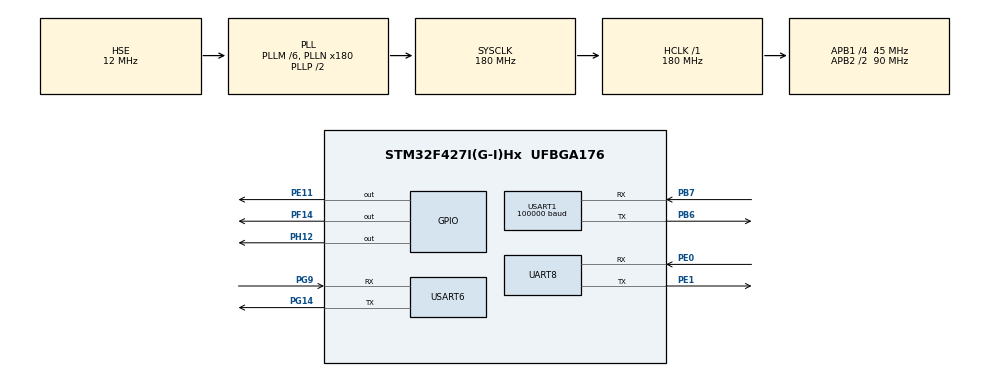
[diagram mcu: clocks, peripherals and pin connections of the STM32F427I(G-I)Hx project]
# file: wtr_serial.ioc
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Dma.Request0=USART1_RX
Dma.USART1_RX.0.Direction=DMA_PERIPH_TO_MEMORY
Dma.USART1_RX.0.FIFOMode=DMA_FIFOMODE_DISABLE
Dma.USART1_RX.0.Instance=DMA2_Stream2
Dma.USART1_RX.0.MemDataAlignment=DMA_MDATAALIGN_BYTE
Dma.USART1_RX.0.MemInc=DMA_MINC_ENABLE
Dma.USART1_RX.0.Mode=DMA_CIRCULAR
Dma.USART1_RX.0.PeriphDataAlignment=DMA_PDATAALIGN_BYTE
Dma.USART1_RX.0.PeriphInc=DMA_PINC_DISABLE
Dma.USART1_RX.0.Priority=DMA_PRIORITY_LOW
FREERTOS.Tasks01=defaultTask,0,256,StartDefaultTask,As weak,NULL,Dynamic,NULL,NULL
FREERTOS.configENABLE_FPU=1
FREERTOS.configGENERATE_RUN_TIME_STATS=1
FREERTOS.configTOTAL_HEAP_SIZE=65536
FREERTOS.configUSE_COUNTING_SEMAPHORES=1
FREERTOS.configUSE_NEWLIB_REENTRANT=1
FREERTOS.configUSE_RECURSIVE_MUTEXES=1
FREERTOS.configUSE_STATS_FORMATTING_FUNCTIONS=1
FREERTOS.configUSE_TRACE_FACILITY=1
Mcu.Family=STM32F4
Mcu.Name=STM32F427I(G-I)Hx
Mcu.Package=UFBGA176
NVIC.DMA2_Stream2_IRQn=true\:5\:0\:false\:false\:true\:true\:false\:true\:true
NVIC.PriorityGroup=NVIC_PRIORITYGROUP_4
NVIC.TIM7_IRQn=true\:15\:0\:false\:false\:true\:false\:false\:true\:true
NVIC.TimeBase=TIM7_IRQn
NVIC.TimeBaseIP=TIM7
NVIC.UART8_IRQn=true\:5\:0\:false\:false\:true\:true\:true\:true\:true
NVIC.USART6_IRQn=true\:5\:0\:false\:false\:true\:true\:true\:true\:true
PA13.Mode=Serial_Wire
PA13.Signal=SYS_JTMS-SWDIO
PA14.Mode=Serial_Wire
PA14.Signal=SYS_JTCK-SWCLK
PB6.Mode=Asynchronous
PB6.Signal=USART1_TX
PB7.Mode=Asynchronous
PB7.Signal=USART1_RX
PE0.Mode=Asynchronous
PE0.Signal=UART8_RX
PE1.Mode=Asynchronous
PE1.Signal=UART8_TX
PE11.Signal=GPIO_Output
PF14.Signal=GPIO_Output
PG14.Mode=Asynchronous
PG14.Signal=USART6_TX
PG9.Mode=Asynchronous
PG9.Signal=USART6_RX
PH0/OSC_IN.Mode=HSE-External-Oscillator
PH0/OSC_IN.Signal=RCC_OSC_IN
PH1/OSC_OUT.Mode=HSE-External-Oscillator
PH1/OSC_OUT.Signal=RCC_OSC_OUT
PH12.Signal=GPIO_Output
ProjectManager.HeapSize=0x200
ProjectManager.StackSize=0x400
ProjectManager.TargetToolchain=Makefile
RCC.48MHZClocksFreq_Value=90000000
RCC.AHBFreq_Value=180000000
RCC.APB1CLKDivider=RCC_HCLK_DIV4
RCC.APB1Freq_Value=45000000
RCC.APB1TimFreq_Value=90000000
RCC.APB2CLKDivider=RCC_HCLK_DIV2
RCC.APB2Freq_Value=90000000
RCC.APB2TimFreq_Value=180000000
RCC.CortexFreq_Value=180000000
RCC.HCLKFreq_Value=180000000
RCC.HSE_VALUE=12000000
RCC.HSI_VALUE=16000000
RCC.LSE_VALUE=32768
RCC.PLLM=6
RCC.PLLN=180
RCC.PLLSourceVirtual=RCC_PLLSOURCE_HSE
RCC.SYSCLKFreq_VALUE=180000000
RCC.SYSCLKSource=RCC_SYSCLKSOURCE_PLLCLK
RCC.VCOOutputFreq_Value=360000000
UART8.VirtualMode=Asynchronous
USART1.BaudRate=100000
USART1.VirtualMode=VM_ASYNC
USART6.VirtualMode=VM_ASYNC
VP_FREERTOS_VS_CMSIS_V1.Mode=CMSIS_V1
VP_SYS_VS_tim7.Mode=TIM7
board=custom

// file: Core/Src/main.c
/* USER CODE BEGIN Header */
/**
  ******************************************************************************
  * @file           : main.c
  * @brief          : Main program body
  ******************************************************************************
  * @attention
  *
  * Copyright (c) 2023 STMicroelectronics.
  * All rights reserved.
  *
  * This software is licensed under terms that can be found in the LICENSE file
  * in the root directory of this software component.
  * If no LICENSE file comes with this software, it is provided AS-IS.
  *
  ******************************************************************************
  */
/* USER CODE END Header */
#include "main.h"
#include "cmsis_os.h"
#include "dma.h"
#include "usart.h"
#include "gpio.h"

void SystemClock_Config(void);
void MX_FREERTOS_Init(void);

int main(void)
{

  /* MCU Configuration--------------------------------------------------------*/

  /* Reset of all peripherals, Initializes the Flash interface and the Systick. */
  HAL_Init();

  /* Configure the system clock */
  SystemClock_Config();

  /* Initialize all configured peripherals */
  MX_GPIO_Init();
  MX_DMA_Init();
  MX_USART1_UART_Init();
  MX_UART8_Init();
  MX_USART6_UART_Init();

  /* Call init function for freertos objects (in freertos.c) */
  MX_FREERTOS_Init();

  /* Start scheduler */
  osKernelStart();

  /* We should never get here as control is now taken by the scheduler */
  /* Infinite loop */
  /* USER CODE BEGIN WHILE */
  while (1)
  {
    // HAL_GPIO_TogglePin(GPIOE, GPIO_PIN_11);
    // HAL_Delay(1000);
    /* USER CODE END WHILE */

  }
}

void SystemClock_Config(void)
{
  RCC_OscInitTypeDef RCC_OscInitStruct = {0};
  RCC_ClkInitTypeDef RCC_ClkInitStruct = {0};

  /** Configure the main internal regulator output voltage
  */
  __HAL_RCC_PWR_CLK_ENABLE();
  __HAL_PWR_VOLTAGESCALING_CONFIG(PWR_REGULATOR_VOLTAGE_SCALE1);

  /** Initializes the RCC Oscillators according to the specified parameters
  * in the RCC_OscInitTypeDef structure.
  */
  RCC_OscInitStruct.OscillatorType = RCC_OSCILLATORTYPE_HSE;
  RCC_OscInitStruct.HSEState = RCC_HSE_ON;
  RCC_OscInitStruct.PLL.PLLState = RCC_PLL_ON;
  RCC_OscInitStruct.PLL.PLLSource = RCC_PLLSOURCE_HSE;
  RCC_OscInitStruct.PLL.PLLM = 6;
  RCC_OscInitStruct.PLL.PLLN = 180;
  RCC_OscInitStruct.PLL.PLLP = RCC_PLLP_DIV2;
  RCC_OscInitStruct.PLL.PLLQ = 4;
  if (HAL_RCC_OscConfig(&RCC_OscInitStruct) != HAL_OK)
  {
    Error_Handler();
  }

  /** Activate the Over-Drive mode
  */
  if (HAL_PWREx_EnableOverDrive() != HAL_OK)
  {
    Error_Handler();
  }

  /** Initializes the CPU, AHB and APB buses clocks
  */
  RCC_ClkInitStruct.ClockType = RCC_CLOCKTYPE_HCLK|RCC_CLOCKTYPE_SYSCLK
                              |RCC_CLOCKTYPE_PCLK1|RCC_CLOCKTYPE_PCLK2;
  RCC_ClkInitStruct.SYSCLKSource = RCC_SYSCLKSOURCE_PLLCLK;
  RCC_ClkInitStruct.AHBCLKDivider = RCC_SYSCLK_DIV1;
  RCC_ClkInitStruct.APB1CLKDivider = RCC_HCLK_DIV4;
  RCC_ClkInitStruct.APB2CLKDivider = RCC_HCLK_DIV2;

  if (HAL_RCC_ClockConfig(&RCC_ClkInitStruct, FLASH_LATENCY_5) != HAL_OK)
  {
    Error_Handler();
  }
}

void HAL_TIM_PeriodElapsedCallback(TIM_HandleTypeDef *htim)
{
  if (htim->Instance == TIM7) {
    HAL_IncTick();
  }
}

void Error_Handler(void)
{
  __disable_irq();
  while (1)
  {
  }
}

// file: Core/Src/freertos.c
/* USER CODE BEGIN Header */
/**
  ******************************************************************************
  * File Name          : freertos.c
  * Description        : Code for freertos applications
  ******************************************************************************
  * @attention
  *
  * Copyright (c) 2023 STMicroelectronics.
  * All rights reserved.
  *
  * This software is licensed under terms that can be found in the LICENSE file
  * in the root directory of this software component.
  * If no LICENSE file comes with this software, it is provided AS-IS.
  *
  ******************************************************************************
  */
/* USER CODE END Header */

#include "FreeRTOS.h"
#include "task.h"
#include "main.h"
#include "cmsis_os.h"

/* USER CODE BEGIN Includes */
#include "usr_main.h"
/* USER CODE END Includes */

osThreadId defaultTaskHandle;

void StartDefaultTask(void const * argument);

void MX_FREERTOS_Init(void); /* (MISRA C 2004 rule 8.1) */

/* GetIdleTaskMemory prototype (linked to static allocation support) */
void vApplicationGetIdleTaskMemory( StaticTask_t **ppxIdleTaskTCBBuffer, StackType_t **ppxIdleTaskStackBuffer, uint32_t *pulIdleTaskStackSize );

/* Hook prototypes */
void configureTimerForRunTimeStats(void);
unsigned long getRunTimeCounterValue(void);

/* USER CODE BEGIN 1 */
/* Functions needed when configGENERATE_RUN_TIME_STATS is on */
__weak void configureTimerForRunTimeStats(void)
{

}

__weak unsigned long getRunTimeCounterValue(void)
{
return 0;
}
/* USER CODE END 1 */

/* USER CODE BEGIN GET_IDLE_TASK_MEMORY */
static StaticTask_t xIdleTaskTCBBuffer;
static StackType_t xIdleStack[configMINIMAL_STACK_SIZE];

void vApplicationGetIdleTaskMemory( StaticTask_t **ppxIdleTaskTCBBuffer, StackType_t **ppxIdleTaskStackBuffer, uint32_t *pulIdleTaskStackSize )
{
  *ppxIdleTaskTCBBuffer = &xIdleTaskTCBBuffer;
  *ppxIdleTaskStackBuffer = &xIdleStack[0];
  *pulIdleTaskStackSize = configMINIMAL_STACK_SIZE;
  /* place for user code */
}
/* USER CODE END GET_IDLE_TASK_MEMORY */

void MX_FREERTOS_Init(void) {

  /* Create the thread(s) */
  /* definition and creation of defaultTask */
  osThreadDef(defaultTask, StartDefaultTask, osPriorityNormal, 0, 256);
  defaultTaskHandle = osThreadCreate(osThread(defaultTask), NULL);

  /* USER CODE BEGIN RTOS_THREADS */
  /* add threads, ... */
  USER_INIT();
  /* USER CODE END RTOS_THREADS */

}

__weak void StartDefaultTask(void const * argument)
{
  for(;;)
  {
    osDelay(1);
  }
}
